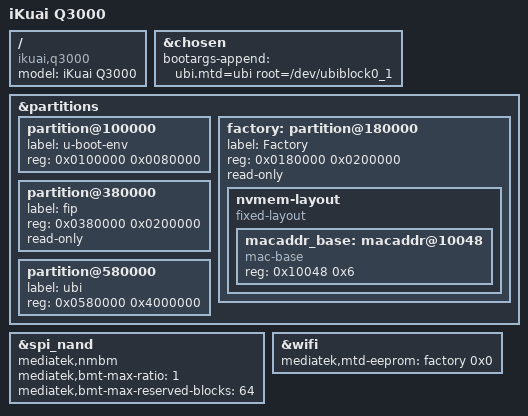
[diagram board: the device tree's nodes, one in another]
// SPDX-License-Identifier: (GPL-2.0 OR MIT)

/dts-v1/;
#include "mt7981b-ikuai-q3000.dtsi"

/ {
	model = "iKuai Q3000";
	compatible = "ikuai,q3000", "mediatek,mt7981";
};

&chosen {
	bootargs-append = " ubi.mtd=ubi root=/dev/ubiblock0_1";
};

&partitions {
	partition@100000 {
		label = "u-boot-env";
		reg = <0x0100000 0x0080000>;
	};

	factory: partition@180000 {
		label = "Factory";
		reg = <0x0180000 0x0200000>;
		read-only;

		nvmem-layout {
			compatible = "fixed-layout";
			#address-cells = <1>;
			#size-cells = <1>;

			macaddr_base: macaddr@10048 {
				compatible = "mac-base";
				reg = <0x10048 0x6>;
				#nvmem-cell-cells = <1>;
			};
		};
	};

	partition@380000 {
		label = "fip";
		reg = <0x0380000 0x0200000>;
		read-only;
	};

	partition@580000 {
		label = "ubi";
		reg = <0x0580000 0x4000000>;
	};
};

&spi_nand {
	mediatek,nmbm;
	mediatek,bmt-max-ratio = <1>;
	mediatek,bmt-max-reserved-blocks = <64>;
};

&wifi {
	status = "okay";
	mediatek,mtd-eeprom = <&factory 0x0>;
};
